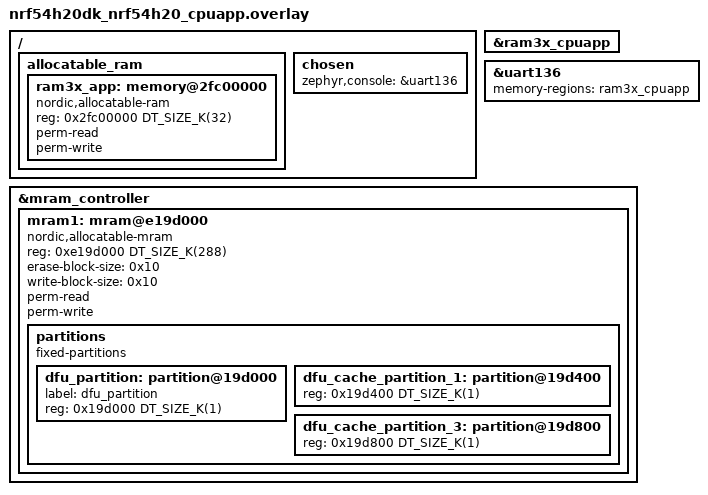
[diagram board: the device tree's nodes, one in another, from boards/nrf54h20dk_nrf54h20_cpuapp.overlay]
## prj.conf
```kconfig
#
# Copyright (c) 2024 Nordic Semiconductor ASA
#
# SPDX-License-Identifier: LicenseRef-Nordic-5-Clause
#

CONFIG_ZTEST=y
CONFIG_ZTEST_NEW_API=y

CONFIG_SUIT_PLATFORM_VARIANT_APP=y

CONFIG_SUIT=y
CONFIG_SUIT_PROCESSOR=y
CONFIG_SUIT_PLATFORM=y

CONFIG_SUIT_MEMPTR_STORAGE=y
CONFIG_SUIT_STREAM=y
CONFIG_SUIT_STREAM_SOURCE_MEMPTR=y
CONFIG_SUIT_STREAM_SINK_MEMPTR=y
CONFIG_SUIT_STREAM_SINK_FLASH=y
CONFIG_SUIT_STREAM_SINK_DIGEST=y
CONFIG_SUIT_SINK_SELECTOR=y

CONFIG_SUIT_UTILS=y
CONFIG_SUIT_CACHE=y
CONFIG_SUIT_CACHE_RW=y
CONFIG_SUIT_STREAM_SINK_CACHE=y
CONFIG_SUIT_STREAM_SOURCE_CACHE=y

CONFIG_ZCBOR=y
CONFIG_ZCBOR_CANONICAL=y

CONFIG_FLASH=y

CONFIG_SUIT_EXECUTION_MODE=y

CONFIG_SUIT_MCI=y
CONFIG_SUIT_METADATA=y

CONFIG_SUIT_CRYPTO=y
CONFIG_SUIT_DIGEST=y
CONFIG_SUIT_CHECK_IMAGE_MATCH=y
```

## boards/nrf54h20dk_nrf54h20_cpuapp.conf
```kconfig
#
# Copyright (c) 2024 Nordic Semiconductor ASA
#
# SPDX-License-Identifier: LicenseRef-Nordic-5-Clause
#

CONFIG_NULL_POINTER_EXCEPTION_DETECTION_NONE=y
CONFIG_SERIAL=y
CONFIG_CONSOLE=y
CONFIG_UART_CONSOLE=y

#Logging and printk is using standard UART.
CONFIG_LOG_MODE_DEFERRED=y
CONFIG_LOG_BACKEND_UART=y
CONFIG_LOG_PRINTK=y
CONFIG_LOG_BUFFER_SIZE=8192
CONFIG_SOC_FLASH_NRF_MRAM_ONE_BYTE_WRITE_ACCESS=y
CONFIG_SUIT_CACHEX_ERASE_BLOCK_SIZE=128
```

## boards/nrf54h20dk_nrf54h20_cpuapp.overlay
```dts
/*
 * Copyright (c) 2024 Nordic Semiconductor ASA
 *
 * SPDX-License-Identifier: LicenseRef-Nordic-5-Clause
 */

 / {
	allocatable_ram {
		#address-cells = <1>;
		#size-cells = <1>;

		/* Allow to use defined RAM3x region by App and cores owned by
		 * App, including UART DMA buffer.
		 */
		ram3x_app: memory@2fc00000 {
			compatible = "nordic,allocatable-ram";
			reg = <0x2fc00000 DT_SIZE_K(32)>;
			perm-read;
			perm-write;
		};
	};

	chosen {
		zephyr,console = &uart136;
	};
};

/* ram3x_cpuapp buffer is used by App core UART driver. */
&ram3x_cpuapp {
	status = "okay";
};

/* Configure UART with test output. */
&uart136 {
	status = "okay";
	memory-regions = <&ram3x_cpuapp>;
};

/delete-node/ &mram1;
&mram_controller {
	mram1: mram@e19d000 {
		compatible = "nordic,allocatable-mram", "soc-nv-flash";
		reg = < 0xe19d000 DT_SIZE_K(288) >;
		erase-block-size = < 0x10 >;
		/* Hardcoded inside the soc_flash_nrf_mram.c (MRAM_WORD_SIZE) */
		write-block-size = < 0x10 >;

		perm-read;
		perm-write;

		partitions {
			compatible = "fixed-partitions";
			#address-cells = < 0x1 >;
			#size-cells = < 0x1 >;

			dfu_partition: partition@19d000 {
				label = "dfu_partition";
				reg = < 0x19d000 DT_SIZE_K(1) >;
			};

			dfu_cache_partition_1: partition@19d400 {
				reg = <0x19d400 DT_SIZE_K(1)>;
			};

			dfu_cache_partition_3: partition@19d800 {
				reg = <0x19d800 DT_SIZE_K(1)>;
			};
		};
	};
};
```

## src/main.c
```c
/*
 * Copyright (c) 2024 Nordic Semiconductor ASA
 *
 * SPDX-License-Identifier: LicenseRef-Nordic-5-Clause
 */

#include <zephyr/ztest.h>
#include <zephyr/drivers/flash.h>
#include <zephyr/storage/flash_map.h>
#include <suit_sink.h>
#include <suit_platform.h>
#include <suit_dfu_cache_sink.h>
#include <suit_dfu_cache_rw.h>
#include <suit_plat_mem_util.h>
#include <suit_types.h>
#include <suit_metadata.h>
#include <zephyr/fff.h>

DEFINE_FFF_GLOBALS;

static uint8_t uri[] = "http://databucket.com";
static uint8_t data[] = { 0x43, 0x60, 0x02, 0x11, 0x35, 0x85, 0x37, 0x85, 0x76,
			 					0x44, 0x09, 0xDE, 0xAD, 0x44, 0x45, 0x42, 0x66, 0x25,
			 					0x12, 0x36, 0x84, 0x00, 0x08, 0x61, 0x17 };
static uint8_t valid_digest[] = { 0x0c, 0xfd, 0xd2, 0x46, 0xb1, 0x84, 0x77, 0x9e, 0xc0,
									0xb5, 0x0b, 0xca, 0xf1, 0xea, 0x0d, 0xaf, 0x2b, 0x18,
									0xa5, 0xbe, 0x5b, 0x61, 0x24, 0xc2, 0x65, 0x1c, 0xa9,
									0xd7, 0x29, 0x96, 0x37, 0xa8 };
static struct zcbor_string exp_digest = {
	.value = valid_digest,
	.len = sizeof(valid_digest),
};

static uint8_t invalid_digest[] = { 0x0c, 0xfd, 0xd2, 0x46, 0xb1, 0x84, 0x77, 0x9e, 0xc0,
									0xb5, 0x0b, 0xca, 0xf1, 0xea, 0x0d, 0xaf, 0x2b, 0x18,
									0xa5, 0xbe, 0x5b, 0x61, 0x24, 0xc2, 0x65, 0x1c, 0xa9,
									0xd7, 0x29, 0x96, 0x37, 0xa7 }; /* Last byte changed */
static struct zcbor_string unexp_digest = {
	.value = invalid_digest,
	.len = sizeof(invalid_digest),
};

/* Mocks of functions provided via SSF services */
FAKE_VALUE_FUNC(int, suit_plat_component_compatibility_check, suit_manifest_class_id_t*,
                struct zcbor_string*);
FAKE_VALUE_FUNC(int, suit_plat_authorize_sequence_num, enum suit_command_sequence,
                struct zcbor_string*, unsigned int);
FAKE_VALUE_FUNC(int, suit_plat_authorize_unsigned_manifest, struct zcbor_string*);
FAKE_VALUE_FUNC(int, suit_plat_authenticate_manifest, struct zcbor_string*, enum suit_cose_alg,
		struct zcbor_string*, struct zcbor_string*, struct zcbor_string*);


void setup_dfu_test_cache(void *f)
{
	int ret = suit_dfu_cache_rw_initialize(NULL, 0);
	zassert_equal(ret, SUIT_PLAT_SUCCESS, "Failed to initialize cache: %i", ret);
}

void clear_dfu_test_partitions(void *f)
{
	/* Erase the area, to meet the preconditions in the next test. */
	const struct device *fdev = DEVICE_DT_GET(DT_CHOSEN(zephyr_flash_controller));
	zassert_not_null(fdev, "Unable to find a driver to erase area");

	int rc = flash_erase(fdev, FIXED_PARTITION_OFFSET(dfu_cache_partition_1),
			     FIXED_PARTITION_SIZE(dfu_cache_partition_1));
	zassert_equal(rc, 0, "Unable to erase dfu__cache_partition_1 before test execution: %i",
		      rc);

	rc = flash_erase(fdev, FIXED_PARTITION_OFFSET(dfu_cache_partition_3),
			 FIXED_PARTITION_SIZE(dfu_cache_partition_3));
	zassert_equal(rc, 0, "Unable to erase dfu_cache_partition_3 before test execution: %i", rc);

	suit_dfu_cache_rw_deinitialize();
}

ZTEST_SUITE(cache_pool_digest_tests, NULL, NULL, setup_dfu_test_cache, clear_dfu_test_partitions, NULL);

ZTEST(cache_pool_digest_tests, test_cache_get_slot_ok)
{
	struct stream_sink sink;

	int ret = suit_dfu_cache_sink_get(&sink, 1, uri, sizeof(uri), true);
	zassert_equal(ret, SUIT_PLAT_SUCCESS, "Failed to get sink: %i", ret);

	ret = sink.write(sink.ctx, data, sizeof(data));
	zassert_equal(ret, SUIT_PLAT_SUCCESS, "Failed to write to sink: %i", ret);

	ret = suit_dfu_cache_sink_commit(sink.ctx);
	zassert_equal(ret, SUIT_PLAT_SUCCESS, "Failed to commit to cache: %i", ret);

	ret = sink.release(sink.ctx);
	zassert_equal(ret, SUIT_PLAT_SUCCESS, "Failed to release sink: %i", ret);

	const uint8_t *payload = NULL;
	size_t payload_size = 0;
	const uint8_t ok_uri[] = "http://databucket.com";
	size_t uri_size = sizeof("http://databucket.com");

	ret = suit_dfu_cache_search(ok_uri, uri_size, &payload, &payload_size);
	zassert_equal(ret, SUIT_PLAT_SUCCESS, "\nGet from cache failed: %i", ret);
	zassert_equal(payload_size, sizeof(data),
		      "Invalid data size for retrieved payload. payload(%u) data(%u)", payload_size,
		      sizeof(data));


	/* Valid id value for cand_img component */
	static uint8_t valid_cand_img_component_id_value[] = {0x82, 0x49, 0x68, 'C', 'A',  'N', 'D',
									'_',  'I',  'M',	'G', 0x41, 0x00};
	/* Valid cand_img component id */
	struct zcbor_string valid_cand_img_component_id = {
		.value = valid_cand_img_component_id_value,
		.len = sizeof(valid_cand_img_component_id_value),
	};

	suit_component_t dst_component;
	ret = suit_plat_create_component_handle(&valid_cand_img_component_id, &dst_component);
	zassert_equal(SUIT_SUCCESS, ret, "test error - create_component_handle failed: %d", ret);

	struct zcbor_string src_uri = {
		.value = uri,
		.len = sizeof(uri),
	};

	ret = suit_plat_fetch(dst_component, &src_uri);
	zassert_equal(ret, SUIT_SUCCESS, "suit_plat_fetch failed - error %i", ret);

	ret = suit_plat_check_image_match(dst_component, suit_cose_sha256, &exp_digest);
	zassert_equal(ret, SUIT_SUCCESS, "suit_plat_check_image_match failed - error %i", ret);

	ret = suit_plat_check_image_match(dst_component, suit_cose_sha256, &unexp_digest);
	zassert_not_equal(ret, SUIT_SUCCESS, "suit_plat_check_image_match should have failed - digest invalid");

	ret = suit_plat_release_component_handle(dst_component);
	zassert_equal(SUIT_SUCCESS, ret, "test error - failed to cleanup component handle: %d", ret);
};
```
